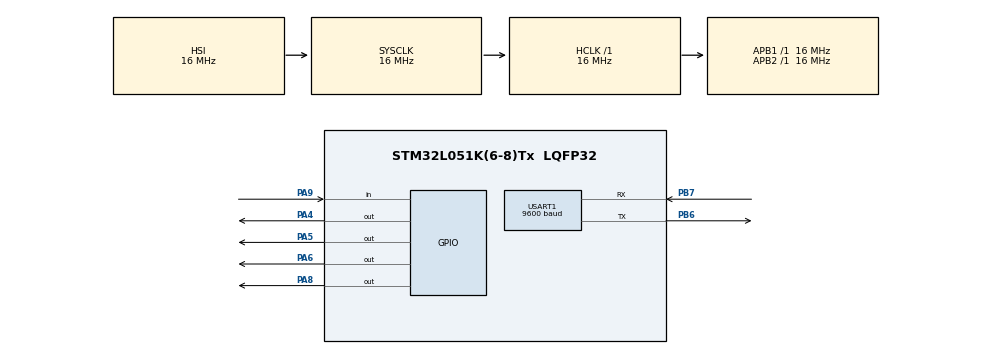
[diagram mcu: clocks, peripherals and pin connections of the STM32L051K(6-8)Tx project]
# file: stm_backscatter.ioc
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Mcu.Family=STM32L0
Mcu.Name=STM32L051K(6-8)Tx
Mcu.Package=LQFP32
PA13.Mode=Serial_Wire
PA13.Signal=SYS_SWDIO
PA14.Mode=Serial_Wire
PA14.Signal=SYS_SWCLK
PA4.GPIO_PuPd=GPIO_NOPULL
PA4.GPIO_Speed=GPIO_SPEED_FREQ_HIGH
PA4.PinState=GPIO_PIN_SET
PA4.Signal=GPIO_Output
PA5.GPIO_Speed=GPIO_SPEED_FREQ_HIGH
PA5.PinState=GPIO_PIN_RESET
PA5.Signal=GPIO_Output
PA6.GPIO_PuPd=GPIO_NOPULL
PA6.GPIO_Speed=GPIO_SPEED_FREQ_HIGH
PA6.PinState=GPIO_PIN_SET
PA6.Signal=GPIO_Output
PA8.GPIO_PuPd=GPIO_PULLDOWN
PA8.GPIO_Speed=GPIO_SPEED_FREQ_VERY_HIGH
PA8.Signal=GPIO_Output
PA9.GPIO_PuPd=GPIO_PULLDOWN
PA9.Signal=GPIO_Input
PB6.GPIO_PuPd=GPIO_PULLUP
PB6.Mode=Asynchronous
PB6.Signal=USART1_TX
PB7.GPIO_PuPd=GPIO_PULLUP
PB7.Mode=Asynchronous
PB7.Signal=USART1_RX
ProjectManager.HeapSize=0x200
ProjectManager.StackSize=0x400
ProjectManager.TargetToolchain=MDK-ARM V5
RCC.AHBFreq_Value=16000000
RCC.APB1Freq_Value=16000000
RCC.APB1TimFreq_Value=16000000
RCC.APB2Freq_Value=16000000
RCC.APB2TimFreq_Value=16000000
RCC.HCLKFreq_Value=16000000
RCC.HSI16_VALUE=16000000
RCC.HSI_VALUE=16000000
RCC.LSE_VALUE=32768
RCC.MSI_VALUE=2097000
RCC.SYSCLKFreq_VALUE=16000000
RCC.SYSCLKSource=RCC_SYSCLKSOURCE_HSI
RCC.VCOOutputFreq_Value=48000000
USART1.BaudRate=9600
USART1.VirtualMode-Asynchronous=VM_ASYNC
board=custom

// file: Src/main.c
/* USER CODE BEGIN Header */
/**
  ******************************************************************************
  * @file           : main.c
  * @brief          : Main program body
  ******************************************************************************
  * @attention
  *
  * <h2><center>&copy; Copyright (c) 2020 STMicroelectronics.
  * All rights reserved.</center></h2>
  *
  * This software component is licensed by ST under BSD 3-Clause license,
  * the "License"; You may not use this file except in compliance with the
  * License. You may obtain a copy of the License at:
  *                        opensource.org/licenses/BSD-3-Clause
  *
  ******************************************************************************
  */
/* USER CODE END Header */

#include "main.h"

/* USER CODE BEGIN Includes */
#include "string.h"
/* USER CODE END Includes */

UART_HandleTypeDef huart1;

void SystemClock_Config(void);
static void MX_GPIO_Init(void);
static void MX_USART1_UART_Init(void);

int main(void)
{

  /* MCU Configuration--------------------------------------------------------*/

  /* Reset of all peripherals, Initializes the Flash interface and the Systick. */
  HAL_Init();

  /* Configure the system clock */
  SystemClock_Config();

  /* Initialize all configured peripherals */
  MX_GPIO_Init();
  MX_USART1_UART_Init();
  /* USER CODE BEGIN 2 */

	uint8_t str_test[] = {2,0,2,0,9,9};
	char str_start[] = "start string\n\r";
	uint32_t cnt_delay = 0;
  /* USER CODE END 2 */

  /* Infinite loop */
  /* USER CODE BEGIN WHILE */
//	HAL_UART_Transmit(&huart1, str_start, strlen(str_start), 0xFFFF);
  while (1)
  {
    /* USER CODE END WHILE */

    /* USER CODE BEGIN 3 */
		HAL_UART_Transmit(&huart1, str_test, 6, 0xFFFF);

		while(++cnt_delay <= 4000000);
		cnt_delay = 0;

  }
  /* USER CODE END 3 */
}

void SystemClock_Config(void)
{
  RCC_OscInitTypeDef RCC_OscInitStruct = {0};
  RCC_ClkInitTypeDef RCC_ClkInitStruct = {0};
  RCC_PeriphCLKInitTypeDef PeriphClkInit = {0};

  /** Configure the main internal regulator output voltage
  */
  __HAL_PWR_VOLTAGESCALING_CONFIG(PWR_REGULATOR_VOLTAGE_SCALE1);
  /** Initializes the CPU, AHB and APB busses clocks
  */
  RCC_OscInitStruct.OscillatorType = RCC_OSCILLATORTYPE_HSI;
  RCC_OscInitStruct.HSIState = RCC_HSI_ON;
  RCC_OscInitStruct.HSICalibrationValue = RCC_HSICALIBRATION_DEFAULT;
  RCC_OscInitStruct.PLL.PLLState = RCC_PLL_NONE;
  if (HAL_RCC_OscConfig(&RCC_OscInitStruct) != HAL_OK)
  {
    Error_Handler();
  }
  /** Initializes the CPU, AHB and APB busses clocks
  */
  RCC_ClkInitStruct.ClockType = RCC_CLOCKTYPE_HCLK|RCC_CLOCKTYPE_SYSCLK
                              |RCC_CLOCKTYPE_PCLK1|RCC_CLOCKTYPE_PCLK2;
  RCC_ClkInitStruct.SYSCLKSource = RCC_SYSCLKSOURCE_HSI;
  RCC_ClkInitStruct.AHBCLKDivider = RCC_SYSCLK_DIV1;
  RCC_ClkInitStruct.APB1CLKDivider = RCC_HCLK_DIV1;
  RCC_ClkInitStruct.APB2CLKDivider = RCC_HCLK_DIV1;

  if (HAL_RCC_ClockConfig(&RCC_ClkInitStruct, FLASH_LATENCY_0) != HAL_OK)
  {
    Error_Handler();
  }
  PeriphClkInit.PeriphClockSelection = RCC_PERIPHCLK_USART1;
  PeriphClkInit.Usart1ClockSelection = RCC_USART1CLKSOURCE_PCLK2;
  if (HAL_RCCEx_PeriphCLKConfig(&PeriphClkInit) != HAL_OK)
  {
    Error_Handler();
  }
}

static void MX_USART1_UART_Init(void)
{

  huart1.Instance = USART1;
  huart1.Init.BaudRate = 9600;
  huart1.Init.WordLength = UART_WORDLENGTH_8B;
  huart1.Init.StopBits = UART_STOPBITS_1;
  huart1.Init.Parity = UART_PARITY_NONE;
  huart1.Init.Mode = UART_MODE_TX_RX;
  huart1.Init.HwFlowCtl = UART_HWCONTROL_NONE;
  huart1.Init.OverSampling = UART_OVERSAMPLING_16;
  huart1.Init.OneBitSampling = UART_ONE_BIT_SAMPLE_DISABLE;
  huart1.AdvancedInit.AdvFeatureInit = UART_ADVFEATURE_NO_INIT;
  if (HAL_UART_Init(&huart1) != HAL_OK)
  {
    Error_Handler();
  }

}

static void MX_GPIO_Init(void)
{
  GPIO_InitTypeDef GPIO_InitStruct = {0};

  /* GPIO Ports Clock Enable */
  __HAL_RCC_GPIOA_CLK_ENABLE();
  __HAL_RCC_GPIOB_CLK_ENABLE();

  /*Configure GPIO pin Output Level */
  HAL_GPIO_WritePin(GPIOA, GPIO_PIN_4|GPIO_PIN_6, GPIO_PIN_SET);

  /*Configure GPIO pin Output Level */
  HAL_GPIO_WritePin(GPIOA, GPIO_PIN_5|GPIO_PIN_8, GPIO_PIN_RESET);

  /*Configure GPIO pins : PA4 PA5 PA6 */
  GPIO_InitStruct.Pin = GPIO_PIN_4|GPIO_PIN_5|GPIO_PIN_6;
  GPIO_InitStruct.Mode = GPIO_MODE_OUTPUT_PP;
  GPIO_InitStruct.Pull = GPIO_NOPULL;
  GPIO_InitStruct.Speed = GPIO_SPEED_FREQ_HIGH;
  HAL_GPIO_Init(GPIOA, &GPIO_InitStruct);

  /*Configure GPIO pin : PA8 */
  GPIO_InitStruct.Pin = GPIO_PIN_8;
  GPIO_InitStruct.Mode = GPIO_MODE_OUTPUT_PP;
  GPIO_InitStruct.Pull = GPIO_PULLDOWN;
  GPIO_InitStruct.Speed = GPIO_SPEED_FREQ_VERY_HIGH;
  HAL_GPIO_Init(GPIOA, &GPIO_InitStruct);

  /*Configure GPIO pin : PA9 */
  GPIO_InitStruct.Pin = GPIO_PIN_9;
  GPIO_InitStruct.Mode = GPIO_MODE_INPUT;
  GPIO_InitStruct.Pull = GPIO_PULLDOWN;
  HAL_GPIO_Init(GPIOA, &GPIO_InitStruct);

}

void Error_Handler(void)
{
}

/************************ (C) COPYRIGHT STMicroelectronics *****END OF FILE****/
